AUTOSAR XML (schema 4-0-3)
package /App_WdgM
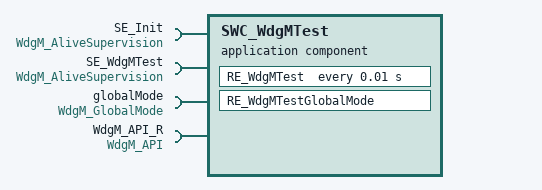
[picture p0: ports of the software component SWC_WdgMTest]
  application sw component type SWC_WdgMTest
    4 x require port:
      SE_Init: required-com-specs=[CheckpointReached, UpdateAliveCounter], required-interface=WdgM_AliveSupervision
      SE_WdgMTest: required-com-specs=[CheckpointReached, UpdateAliveCounter], required-interface=WdgM_AliveSupervision
      globalMode: mode-switch-receiver-com-spec{enhanced-mode-api=false, mode-group=currentMode, supports-asynchronous-mode-switch=false}, required-interface=WdgM_GlobalMode
      WdgM_API_R: required-com-specs=[GetGlobalStatus, GetFirstExpiredSEID, SetMode], required-interface=WdgM_API
    behavior IB_WdgMTest: data-type-mapping=WdgM_Mode
      timing event TE_WdgMTest: start-on-event=RE_WdgMTest, period=0.01
      4 x swc mode switch event, all with start-on-event=RE_WdgMTestGlobalMode, activation=ON-ENTRY:
        SwcModeSwitchEvent_globalMode_OK: mode=globalMode.currentMode.SUPERVISION_OK
        SwcModeSwitchEvent_globalMode_FAILED: mode=globalMode.currentMode.SUPERVISION_FAILED
        SwcModeSwitchEvent_globalMode_EXPIRED: mode=globalMode.currentMode.SUPERVISION_EXPIRED
        SwcModeSwitchEvent_globalMode_STOPPED: mode=globalMode.currentMode.SUPERVISION_STOPPED
      runnable RE_WdgMTest
        4 x sync call:
          SynchronousServerCallPoint_SE10ms_CheckpointReached: operation=SE_WdgMTest.CheckpointReached
          SynchronousServerCallPoint_GetGlobalStatus: operation=WdgM_API_R.GetGlobalStatus
          SynchronousServerCallPoint_GetFirstExpiredSEID: operation=WdgM_API_R.GetFirstExpiredSEID
          SynchronousServerCallPoint_SetMode: operation=WdgM_API_R.SetMode
      runnable RE_WdgMTestGlobalMode: can-be-invoked-concurrently=true, mode-access-point=globalMode.currentMode
  composition sw component type CSWC_WdgM
    component SWC_WdgMTest: type=SWC_WdgMTest
  swc implementation Swc_WdgM_Implementation: behavior=IB_WdgMTest
